VERSION ""

NS_ :

BS_:
BU_: MCU SWU LCU FCCU TCU EDU
BO_ 272 MCU_TIME_SYNC: 8 MCU
   SG_ MCU_TIME_MS : 0|32@1+ (1,0) [0|1] "ms" Vector__XXX
   SG_ MCU_TIME_CLOCK_CYCLES : 32|32@1+ (1,0) [0|1] "" Vector__XXX

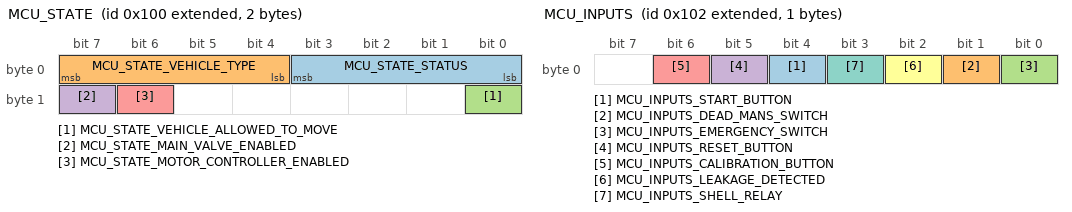
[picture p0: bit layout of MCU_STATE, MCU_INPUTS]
BO_ 2147483904 MCU_STATE: 2 MCU
   SG_ MCU_STATE_STATUS : 0|4@1+ (1,0) [0|15] "" Vector__XXX
   SG_ MCU_STATE_VEHICLE_TYPE : 4|4@1+ (1,0) [0|15] "" Vector__XXX
   SG_ MCU_STATE_VEHICLE_ALLOWED_TO_MOVE : 8|1@1+ (1,0) [0|1] "" Vector__XXX
   SG_ MCU_STATE_MAIN_VALVE_ENABLED : 15|1@1+ (1,0) [0|1] "" Vector__XXX
   SG_ MCU_STATE_MOTOR_CONTROLLER_ENABLED : 14|1@1+ (1,0) [0|1] "" Vector__XXX

BO_ 2147483906 MCU_INPUTS: 1 MCU
   SG_ MCU_INPUTS_START_BUTTON : 4|1@1+ (1,0) [0|1] "" Vector__XXX
   SG_ MCU_INPUTS_DEAD_MANS_SWITCH : 1|1@1+ (1,0) [0|1] "" Vector__XXX
   SG_ MCU_INPUTS_EMERGENCY_SWITCH : 0|1@1+ (1,0) [0|1] "" Vector__XXX
   SG_ MCU_INPUTS_RESET_BUTTON : 5|1@1+ (1,0) [0|1] "" Vector__XXX
   SG_ MCU_INPUTS_CALIBRATION_BUTTON : 6|1@1+ (1,0) [0|1] "" Vector__XXX
   SG_ MCU_INPUTS_LEAKAGE_DETECTED : 2|1@1+ (1,0) [0|1] "" Vector__XXX
   SG_ MCU_INPUTS_SHELL_RELAY : 3|1@1+ (1,0) [0|1] "" Vector__XXX

BO_ 2147483905 MCU_FAULTS: 8 MCU
   SG_ MCU_FAULTS_EMERGENCY_SWITCH : 0|1@1+ (1,0) [0|1] "" Vector__XXX
   SG_ MCU_FAULTS_EMERGENCY_DEAD_MANS_SWITCH : 1|1@1+ (1,0) [0|1] "" Vector__XXX
   SG_ MCU_FAULTS_EMERGENCY_LEAKAGE_DETECTED : 2|1@1+ (1,0) [0|1] "" Vector__XXX
   SG_ MCU_FAULTS_ERROR_SC_V_LOW : 16|1@1+ (1,0) [0|1] "" Vector__XXX
   SG_ MCU_FAULTS_ERROR_SC_V_HIGH : 17|1@1+ (1,0) [0|1] "" Vector__XXX
   SG_ MCU_FAULTS_ERROR_SC_C_LOW : 18|1@1+ (1,0) [0|1] "" Vector__XXX
   SG_ MCU_FAULTS_ERROR_SC_C_HIGH : 19|1@1+ (1,0) [0|1] "" Vector__XXX
   SG_ MCU_FAULTS_ERROR_FC_C_LOW : 10|1@1+ (1,0) [0|1] "" Vector__XXX
   SG_ MCU_FAULTS_ERROR_FC_V_HIGH : 9|1@1+ (1,0) [0|1] "" Vector__XXX
   SG_ MCU_FAULTS_ERROR_FC_V_LOW : 8|1@1+ (1,0) [0|1] "" Vector__XXX
   SG_ MCU_FAULTS_ERROR_FC_C_HIGH : 11|1@1+ (1,0) [0|1] "" Vector__XXX
   SG_ MCU_FAULTS_ERROR_MC_V_LOW : 24|1@1+ (1,0) [0|1] "" Vector__XXX
   SG_ MCU_FAULTS_ERROR_MC_V_HIGH : 25|1@1+ (1,0) [0|1] "" Vector__XXX
   SG_ MCU_FAULTS_ERROR_MC_C_LOW : 26|1@1+ (1,0) [0|1] "" Vector__XXX
   SG_ MCU_FAULTS_ERROR_MC_C_HIGH : 27|1@1+ (1,0) [0|1] "" Vector__XXX
   SG_ MCU_FAULTS_ERROR_AB_V_LOW : 32|1@1+ (1,0) [0|1] "" Vector__XXX
   SG_ MCU_FAULTS_ERROR_AB_V_HIGH : 33|1@1+ (1,0) [0|1] "" Vector__XXX
   SG_ MCU_FAULTS_ERROR_AB_C_LOW : 34|1@1+ (1,0) [0|1] "" Vector__XXX
   SG_ MCU_FAULTS_ERROR_AB_C_HIGH : 35|1@1+ (1,0) [0|1] "" Vector__XXX

BO_ 2147483907 MCU_ANALOG_FC_DRIVER: 4 MCU
   SG_ MCU_ANALOG_FC_ACCELERATION_PEDAL_VOLTAGE : 0|16@1+ (0.0001,0) [0|5] "V" Vector__XXX
   SG_ MCU_ANALOG_FC_BRAKE_PEDAL_VOLTAGE : 16|16@1+ (0.0001,0) [0|5] "V" Vector__XXX

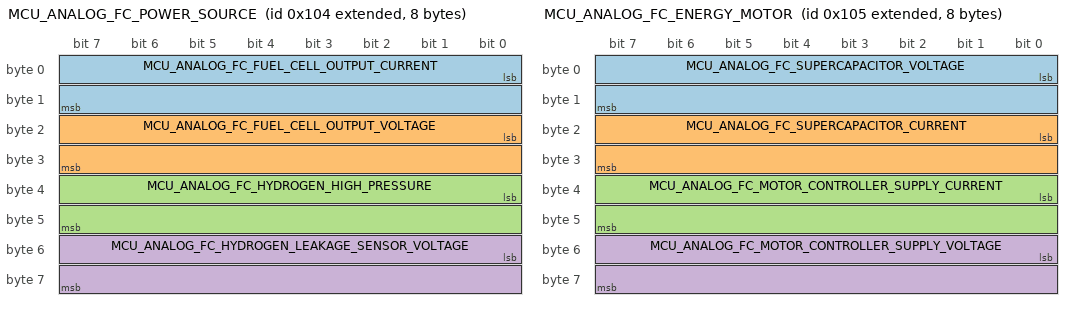
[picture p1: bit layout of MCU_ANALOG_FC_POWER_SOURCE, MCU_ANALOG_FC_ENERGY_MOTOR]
BO_ 2147483908 MCU_ANALOG_FC_POWER_SOURCE: 8 MCU
   SG_ MCU_ANALOG_FC_FUEL_CELL_OUTPUT_CURRENT : 0|16@1+ (0.001,0) [0|40] "A" Vector__XXX
   SG_ MCU_ANALOG_FC_FUEL_CELL_OUTPUT_VOLTAGE : 16|16@1+ (0.001,0) [0|60] "V" Vector__XXX
   SG_ MCU_ANALOG_FC_HYDROGEN_HIGH_PRESSURE : 32|16@1+ (0.1,0) [0|700] "bar" Vector__XXX
   SG_ MCU_ANALOG_FC_HYDROGEN_LEAKAGE_SENSOR_VOLTAGE : 48|16@1+ (0.0001,0) [0|5] "V" Vector__XXX

BO_ 2147483909 MCU_ANALOG_FC_ENERGY_MOTOR: 8 MCU
   SG_ MCU_ANALOG_FC_SUPERCAPACITOR_VOLTAGE : 0|16@1+ (0.001,0) [0|60] "V" Vector__XXX
   SG_ MCU_ANALOG_FC_SUPERCAPACITOR_CURRENT : 16|16@1+ (0.01,0) [0|120] "A" Vector__XXX
   SG_ MCU_ANALOG_FC_MOTOR_CONTROLLER_SUPPLY_CURRENT : 32|16@1+ (0.001,0) [0|60] "A" Vector__XXX
   SG_ MCU_ANALOG_FC_MOTOR_CONTROLLER_SUPPLY_VOLTAGE : 48|16@1+ (0.001,0) [0|60] "V" Vector__XXX

BO_ 2147483910 MCU_ANALOG_FC_ACCESSORY: 4 MCU
   SG_ MCU_ANALOG_FC_ACCESSORY_BATTERY_CURRENT : 0|16@1+ (0.001,0) [0|60] "A" Vector__XXX
   SG_ MCU_ANALOG_FC_ACCESSORY_BATTERY_VOLTAGE : 16|16@1+ (0.001,0) [0|20] "V" Vector__XXX

CM_ BU_ MCU "Master control unit (via Can converter unit)";
CM_ BU_ SWU "Steering wheel unit";
CM_ BU_ LCU "Lighting control unit";
CM_ BU_ FCCU "Fuel cell control unit";
CM_ BU_ TCU "Telemetry control unit";
CM_ BU_ EDU "Electric drive unit";
BA_DEF_ BO_ "GenMsgBackgroundColor" STRING ;
BA_DEF_ BO_ "GenMsgForegroundColor" STRING ;
BA_DEF_ BO_ "filterlabeling" INT 0 0;
BA_DEF_ BO_ "filterlabeling" INT 0 0;
BA_DEF_ BO_ "filterlabeling" INT 0 0;
BA_DEF_ BO_ "filterlabeling" INT 0 0;
BA_DEF_DEF_ "GenMsgBackgroundColor" "#ffffff";
BA_DEF_DEF_ "GenMsgForegroundColor" "#000000";
BA_DEF_DEF_ "filterlabeling" 1;
VAL_ 2147483904 MCU_STATE_STATUS 0 "INIT" 1 "IDLE" 2 "STARTING" 3 "SHUTTING_DOWN" 4 "RUNNING";
VAL_ 2147483904 MCU_STATE_VEHICLE_TYPE 0 "HYDROS_V1" 1 "HYDROS_V2" 2 "BOLID" 3 "HYDRA";
VAL_ 2147483904 MCU_STATE_VEHICLE_ALLOWED_TO_MOVE 0 "VEHICLE_ALLOWED_TO_MOVE" 1 "VEHICLE_NOT_ALLOWED_TO_MOVE";
VAL_ 2147483904 MCU_STATE_MAIN_VALVE_ENABLED 0 "FALSE" 1 "TRUE";
VAL_ 2147483904 MCU_STATE_MOTOR_CONTROLLER_ENABLED 0 "FALSE" 1 "TRUE";
VAL_ 2147483906 MCU_INPUTS_START_BUTTON 0 "RELEASED" 1 "PRESSED";
VAL_ 2147483906 MCU_INPUTS_DEAD_MANS_SWITCH 0 "OFF" 1 "ON";
VAL_ 2147483906 MCU_INPUTS_EMERGENCY_SWITCH 0 "OFF" 1 "ON";
VAL_ 2147483906 MCU_INPUTS_RESET_BUTTON 0 "RELEASED" 1 "PRESSED";
VAL_ 2147483906 MCU_INPUTS_CALIBRATION_BUTTON 0 "RELEASED" 1 "PRESSED";
VAL_ 2147483906 MCU_INPUTS_LEAKAGE_DETECTED 0 "FALSE" 1 "TRUE";
VAL_ 2147483906 MCU_INPUTS_SHELL_RELAY 0 "NOT_ACTIVATED" 1 "ACTIVATED";
VAL_ 2147483905 MCU_FAULTS_EMERGENCY_SWITCH 0 "FALSE" 1 "TRUE";
VAL_ 2147483905 MCU_FAULTS_EMERGENCY_DEAD_MANS_SWITCH 0 "FALSE" 1 "TRUE";
VAL_ 2147483905 MCU_FAULTS_EMERGENCY_LEAKAGE_DETECTED 0 "FALSE" 1 "TRUE";
VAL_ 2147483905 MCU_FAULTS_ERROR_SC_V_LOW 0 "FALSE" 1 "TRUE";
VAL_ 2147483905 MCU_FAULTS_ERROR_SC_V_HIGH 0 "FALSE" 1 "TRUE";
VAL_ 2147483905 MCU_FAULTS_ERROR_SC_C_LOW 0 "FALSE" 1 "TRUE";
VAL_ 2147483905 MCU_FAULTS_ERROR_SC_C_HIGH 0 "FALSE" 1 "TRUE";
VAL_ 2147483905 MCU_FAULTS_ERROR_FC_C_LOW 0 "FALSE" 1 "TRUE";
VAL_ 2147483905 MCU_FAULTS_ERROR_FC_V_HIGH 0 "FALSE" 1 "TRUE";
VAL_ 2147483905 MCU_FAULTS_ERROR_FC_V_LOW 0 "FALSE" 1 "TRUE";
VAL_ 2147483905 MCU_FAULTS_ERROR_FC_C_HIGH 0 "FALSE" 1 "TRUE";
VAL_ 2147483905 MCU_FAULTS_ERROR_MC_V_LOW 0 "FALSE" 1 "TRUE";
VAL_ 2147483905 MCU_FAULTS_ERROR_MC_V_HIGH 0 "FALSE" 1 "TRUE";
VAL_ 2147483905 MCU_FAULTS_ERROR_MC_C_LOW 0 "FALSE" 1 "TRUE";
VAL_ 2147483905 MCU_FAULTS_ERROR_MC_C_HIGH 0 "FALSE" 1 "TRUE";
VAL_ 2147483905 MCU_FAULTS_ERROR_AB_V_LOW 0 "FALSE" 1 "TRUE";
VAL_ 2147483905 MCU_FAULTS_ERROR_AB_V_HIGH 0 "FALSE" 1 "TRUE";
VAL_ 2147483905 MCU_FAULTS_ERROR_AB_C_LOW 0 "FALSE" 1 "TRUE";
VAL_ 2147483905 MCU_FAULTS_ERROR_AB_C_HIGH 0 "FALSE" 1 "TRUE";
